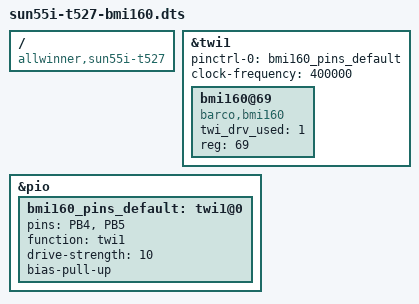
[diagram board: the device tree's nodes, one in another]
/dts-v1/;
/plugin/;

/ {
    compatible = "allwinner,sun55i-t527";
	fragment@0 {
		target = <&twi1>;
		__overlay__ {
			#address-cells = <1>;
			#size-cells = <0>;
			pinctrl-0 = <&bmi160_pins_default>;
			pinctrl-names = "default";
			clock-frequency = <400000>;
			status = "okay";
			bmi160@69 {
				compatible = "barco,bmi160";
				twi_drv_used = <1>;
				reg = <69>;
				status = "okay";
			};
		};
	};

	fragment@1 {
		target = <&pio>;
		__overlay__ {
			bmi160_pins_default: twi1@0 {
				pins = "PB4", "PB5";
				function = "twi1";
				drive-strength = <10>;
				bias-pull-up;
			};
		};
	};


};

/** 反面例子。。。。 */
// / {
// 	fragment@0 {
// 		target = <&pio>;
// 		__overlay__ {
// 			bmi160_pins_default: twi1@0 {
// 				pins = "PB4", "PB5";
// 				function = "twi1";
// 				drive-strength = <10>;
// 				bias-pull-up;
// 			};
// 		};
// 	};

// 	fragment@1 {
// 		target-path = "/";
// 		__overlay__ {
// 		#address-cells = <1>;
// 		#size-cells = <0>;
// 		status = "okay";
// 		bmi160_i2c@69 {
// 				compatible = "barco,bmi160_i2c";
// 				pinctrl-0 = <&bmi160_pins_default>;
// 				pinctrl-names = "default";
// 				clock-frequency = <400000>;
// 				twi_drv_used = <1>;
// 				reg = <69>;
// 				status = "okay";
// 			};
// 		};
// 	};
// };
